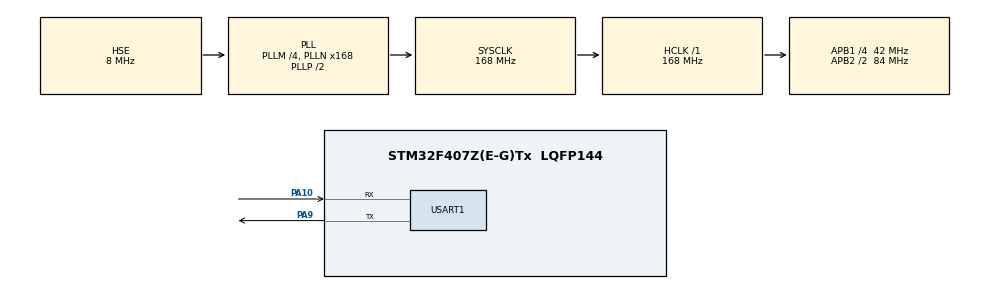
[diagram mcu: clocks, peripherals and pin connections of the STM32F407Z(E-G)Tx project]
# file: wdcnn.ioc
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Mcu.Family=STM32F4
Mcu.Name=STM32F407Z(E-G)Tx
Mcu.Package=LQFP144
NVIC.PriorityGroup=NVIC_PRIORITYGROUP_4
PA10.Mode=Asynchronous
PA10.Signal=USART1_RX
PA13.Mode=Serial_Wire
PA13.Signal=SYS_JTMS-SWDIO
PA14.Mode=Serial_Wire
PA14.Signal=SYS_JTCK-SWCLK
PA9.Mode=Asynchronous
PA9.Signal=USART1_TX
PH0-OSC_IN.Mode=HSE-External-Oscillator
PH0-OSC_IN.Signal=RCC_OSC_IN
PH1-OSC_OUT.Mode=HSE-External-Oscillator
PH1-OSC_OUT.Signal=RCC_OSC_OUT
ProjectManager.HeapSize=0x800
ProjectManager.StackSize=0x800
ProjectManager.TargetToolchain=MDK-ARM V5
RCC.48MHZClocksFreq_Value=84000000
RCC.AHBFreq_Value=168000000
RCC.APB1CLKDivider=RCC_HCLK_DIV4
RCC.APB1Freq_Value=42000000
RCC.APB1TimFreq_Value=84000000
RCC.APB2CLKDivider=RCC_HCLK_DIV2
RCC.APB2Freq_Value=84000000
RCC.APB2TimFreq_Value=168000000
RCC.CortexFreq_Value=168000000
RCC.HCLKFreq_Value=168000000
RCC.HSE_VALUE=8000000
RCC.HSI_VALUE=16000000
RCC.LSE_VALUE=32768
RCC.PLLM=4
RCC.PLLN=168
RCC.PLLSourceVirtual=RCC_PLLSOURCE_HSE
RCC.SYSCLKFreq_VALUE=168000000
RCC.SYSCLKSource=RCC_SYSCLKSOURCE_PLLCLK
RCC.VCOOutputFreq_Value=336000000
STMicroelectronics.X-CUBE-AI.7.3.0.ActivationBufferSizeList=16328
STMicroelectronics.X-CUBE-AI.7.3.0.ActivationBuffers=pool0
STMicroelectronics.X-CUBE-AI.7.3.0.ActivationNames=pool0
STMicroelectronics.X-CUBE-AI.7.3.0.ActivationSizes=AI_WDCNN_DATA_ACTIVATION_1_SIZE
STMicroelectronics.X-CUBE-AI.7.3.0.ApplicationCcDeviceJjApplication=ApplicationTemplate
STMicroelectronics.X-CUBE-AI.7.3.0.HeapSize=0x800
STMicroelectronics.X-CUBE-AI.7.3.0.InternalRamActivationBufferMaxSize=AI_WDCNN_DATA_ACTIVATIONS_SIZE
STMicroelectronics.X-CUBE-AI.7.3.0.MaximumNumberOfInputLayer=1
STMicroelectronics.X-CUBE-AI.7.3.0.MaximumNumberOfOutputLayer=1
STMicroelectronics.X-CUBE-AI.7.3.0.MaximumSizeOfInputLayer=1
STMicroelectronics.X-CUBE-AI.7.3.0.MaximumSizeOfOutputLayer=1
STMicroelectronics.X-CUBE-AI.7.3.0.ModelActualCompression-0bc09e5e5d04df3441566788c231f0678c513310a3338ec8317b5f2e3c015cf6=0.0
STMicroelectronics.X-CUBE-AI.7.3.0.ModelCompression-0bc09e5e5d04df3441566788c231f0678c513310a3338ec8317b5f2e3c015cf6=None
STMicroelectronics.X-CUBE-AI.7.3.0.ModelFlashOccupation-0bc09e5e5d04df3441566788c231f0678c513310a3338ec8317b5f2e3c015cf6=97216
STMicroelectronics.X-CUBE-AI.7.3.0.ModelHashList=0bc09e5e5d04df3441566788c231f0678c513310a3338ec8317b5f2e3c015cf6
STMicroelectronics.X-CUBE-AI.7.3.0.ModelKind-0bc09e5e5d04df3441566788c231f0678c513310a3338ec8317b5f2e3c015cf6=TFLITE
STMicroelectronics.X-CUBE-AI.7.3.0.ModelMacc-0bc09e5e5d04df3441566788c231f0678c513310a3338ec8317b5f2e3c015cf6=726640
STMicroelectronics.X-CUBE-AI.7.3.0.ModelName-0bc09e5e5d04df3441566788c231f0678c513310a3338ec8317b5f2e3c015cf6=wdcnn
STMicroelectronics.X-CUBE-AI.7.3.0.ModelNameList=wdcnn
STMicroelectronics.X-CUBE-AI.7.3.0.ModelRamOccupation-0bc09e5e5d04df3441566788c231f0678c513310a3338ec8317b5f2e3c015cf6=16328
STMicroelectronics.X-CUBE-AI.7.3.0.ModelStructureFile-0bc09e5e5d04df3441566788c231f0678c513310a3338ec8317b5f2e3c015cf6=F\:\\Undergraduate\\FYP\\Project\\ResNet-18\\TF\\WDCNNQuant_v1.tflite
STMicroelectronics.X-CUBE-AI.7.3.0.ModelType-0bc09e5e5d04df3441566788c231f0678c513310a3338ec8317b5f2e3c015cf6=STM32Cube.AI runtime
STMicroelectronics.X-CUBE-AI.7.3.0.ReadyForCodeGeneration=true
STMicroelectronics.X-CUBE-AI.7.3.0.StackSize=0x800
STMicroelectronics.X-CUBE-AI.7.3.0.WorkingBufferStartAddrList=0xFFFFFFFF
STMicroelectronics.X-CUBE-AI.7.3.0.XAaCUBEAaAICcArtificialOoIntelligenceJjCore=true
STMicroelectronics.X-CUBE-AI.7.3.0.copyWeightToRam-0bc09e5e5d04df3441566788c231f0678c513310a3338ec8317b5f2e3c015cf6=false
STMicroelectronics.X-CUBE-AI.7.3.0.customLayerConfigEnabled-0bc09e5e5d04df3441566788c231f0678c513310a3338ec8317b5f2e3c015cf6=false
STMicroelectronics.X-CUBE-AI.7.3.0.useInputAllocation-0bc09e5e5d04df3441566788c231f0678c513310a3338ec8317b5f2e3c015cf6=true
STMicroelectronics.X-CUBE-AI.7.3.0.useOutputAllocation-0bc09e5e5d04df3441566788c231f0678c513310a3338ec8317b5f2e3c015cf6=true
USART1.VirtualMode=VM_ASYNC
VP_CRC_VS_CRC.Mode=CRC_Activate
VP_STMicroelectronics.X-CUBE-AI_VS_ArtificialOoIntelligenceJjXAaCUBEAaAI_7.3.0.Mode=ArtificialOoIntelligenceJjXAaCUBEAaAI
VP_STMicroelectronics.X-CUBE-AI_VS_DeviceJjApplication_7.3.0.Mode=DeviceJjApplication
board=custom

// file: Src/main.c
/* USER CODE BEGIN Header */
/**
  ******************************************************************************
  * @file           : main.c
  * @brief          : Main program body
  ******************************************************************************
  * @attention
  *
  * Copyright (c) 2023 STMicroelectronics.
  * All rights reserved.
  *
  * This software is licensed under terms that can be found in the LICENSE file
  * in the root directory of this software component.
  * If no LICENSE file comes with this software, it is provided AS-IS.
  *
  ******************************************************************************
  */
/* USER CODE END Header */
#include "main.h"
#include "crc.h"
#include "usart.h"
#include "gpio.h"
#include "app_x-cube-ai.h"

/* USER CODE BEGIN Includes */
#include "stdio.h"
/* USER CODE END Includes */

void SystemClock_Config(void);

int main(void)
{

  /* MCU Configuration--------------------------------------------------------*/

  /* Reset of all peripherals, Initializes the Flash interface and the Systick. */
  HAL_Init();

  /* Configure the system clock */
  SystemClock_Config();

  /* Initialize all configured peripherals */
  MX_GPIO_Init();
  MX_CRC_Init();
  MX_USART1_UART_Init();
  /* USER CODE BEGIN 2 */
  MX_X_CUBE_AI_Init();
  /* USER CODE END 2 */

  /* USER CODE BEGIN WHILE */
  // while (1)
  // {
    /* USER CODE END WHILE */
  MX_X_CUBE_AI_Process();
    /* USER CODE BEGIN 3 */
  // }
  /* USER CODE END 3 */
  return 0;
}

void SystemClock_Config(void)
{
  RCC_OscInitTypeDef RCC_OscInitStruct = {0};
  RCC_ClkInitTypeDef RCC_ClkInitStruct = {0};

  /** Configure the main internal regulator output voltage
  */
  __HAL_RCC_PWR_CLK_ENABLE();
  __HAL_PWR_VOLTAGESCALING_CONFIG(PWR_REGULATOR_VOLTAGE_SCALE1);

  /** Initializes the RCC Oscillators according to the specified parameters
  * in the RCC_OscInitTypeDef structure.
  */
  RCC_OscInitStruct.OscillatorType = RCC_OSCILLATORTYPE_HSE;
  RCC_OscInitStruct.HSEState = RCC_HSE_ON;
  RCC_OscInitStruct.PLL.PLLState = RCC_PLL_ON;
  RCC_OscInitStruct.PLL.PLLSource = RCC_PLLSOURCE_HSE;
  RCC_OscInitStruct.PLL.PLLM = 4;
  RCC_OscInitStruct.PLL.PLLN = 168;
  RCC_OscInitStruct.PLL.PLLP = RCC_PLLP_DIV2;
  RCC_OscInitStruct.PLL.PLLQ = 4;
  if (HAL_RCC_OscConfig(&RCC_OscInitStruct) != HAL_OK)
  {
    Error_Handler();
  }

  /** Initializes the CPU, AHB and APB buses clocks
  */
  RCC_ClkInitStruct.ClockType = RCC_CLOCKTYPE_HCLK|RCC_CLOCKTYPE_SYSCLK
                              |RCC_CLOCKTYPE_PCLK1|RCC_CLOCKTYPE_PCLK2;
  RCC_ClkInitStruct.SYSCLKSource = RCC_SYSCLKSOURCE_PLLCLK;
  RCC_ClkInitStruct.AHBCLKDivider = RCC_SYSCLK_DIV1;
  RCC_ClkInitStruct.APB1CLKDivider = RCC_HCLK_DIV4;
  RCC_ClkInitStruct.APB2CLKDivider = RCC_HCLK_DIV2;

  if (HAL_RCC_ClockConfig(&RCC_ClkInitStruct, FLASH_LATENCY_5) != HAL_OK)
  {
    Error_Handler();
  }
}

void Error_Handler(void)
{
  __disable_irq();
  while (1)
  {
  }
}
